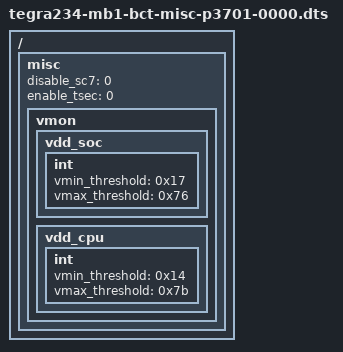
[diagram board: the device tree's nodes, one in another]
/*
 * Copyright (c) 2021, NVIDIA CORPORATION.  All rights reserved.
 *
 * This program is free software; you can redistribute it and/or modify
 * it under the terms of the GNU General Public License as published by
 * the Free Software Foundation; either version 2 of the License, or
 * (at your option) any later version.
 *
 * This program is distributed in the hope that it will be useful, but WITHOUT
 * ANY WARRANTY; without even the implied warranty of MERCHANTABILITY or
 * FITNESS FOR A PARTICULAR PURPOSE.  See the GNU General Public License for
 * more details.
 */

/dts-v1/;

#include "tegrabl_carveout_id.h"
#include "tegra234-mb1-bct-misc-common.dtsi"
#include "tegra234-mb1-bct-carveout-l4t.dtsi"

/ {
    misc {
        disable_sc7 = <0>;
        enable_tsec = <0>;
        vmon {
            vdd_soc {
                int {
                    vmin_threshold = <0x17>;
                    vmax_threshold = <0x76>;
                };
            };
            vdd_cpu {
                int {
                    vmin_threshold = <0x14>;
                    vmax_threshold = <0x7b>;
                };
            };
        };
    };
};
